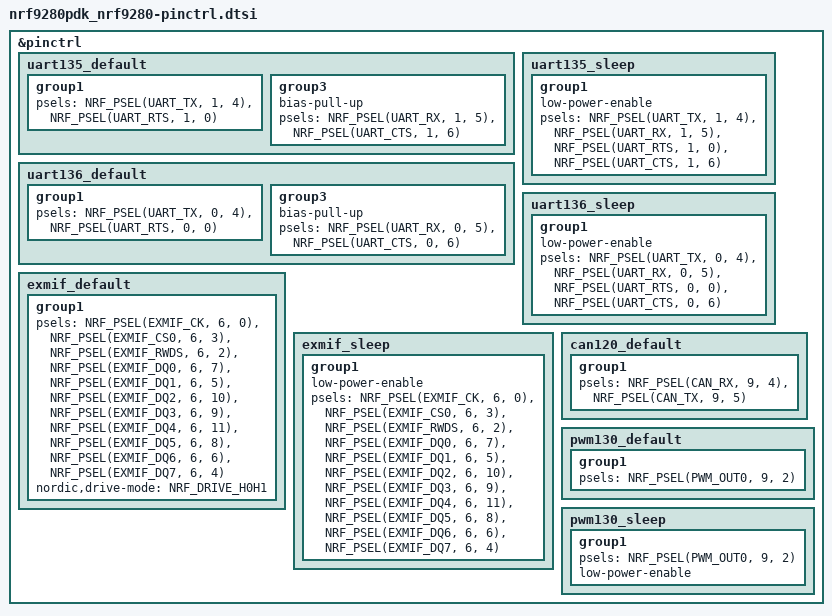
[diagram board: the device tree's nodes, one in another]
/*
 * Copyright (c) 2024 Nordic Semiconductor ASA
 *
 * SPDX-License-Identifier: Apache-2.0
 */

&pinctrl {
	/omit-if-no-ref/ uart135_default: uart135_default {
		group1 {
			psels = <NRF_PSEL(UART_TX, 1, 4)>,
				<NRF_PSEL(UART_RTS, 1, 0)>;
		};

		group3 {
			bias-pull-up;
			psels = <NRF_PSEL(UART_RX, 1, 5)>,
				<NRF_PSEL(UART_CTS, 1, 6)>;
		};
	};

	/omit-if-no-ref/ uart135_sleep: uart135_sleep {
		group1 {
			low-power-enable;
			psels = <NRF_PSEL(UART_TX, 1, 4)>,
				<NRF_PSEL(UART_RX, 1, 5)>,
				<NRF_PSEL(UART_RTS, 1, 0)>,
				<NRF_PSEL(UART_CTS, 1, 6)>;
		};
	};

	/omit-if-no-ref/ uart136_default: uart136_default {
		group1 {
			psels = <NRF_PSEL(UART_TX, 0, 4)>,
				<NRF_PSEL(UART_RTS, 0, 0)>;
		};

		group3 {
			bias-pull-up;
			psels = <NRF_PSEL(UART_RX, 0, 5)>,
				<NRF_PSEL(UART_CTS, 0, 6)>;
		};
	};

	/omit-if-no-ref/ uart136_sleep: uart136_sleep {
		group1 {
			low-power-enable;
			psels = <NRF_PSEL(UART_TX, 0, 4)>,
				<NRF_PSEL(UART_RX, 0, 5)>,
				<NRF_PSEL(UART_RTS, 0, 0)>,
				<NRF_PSEL(UART_CTS, 0, 6)>;
		};
	};

	/omit-if-no-ref/ exmif_default: exmif_default {
		group1 {
			psels = <NRF_PSEL(EXMIF_CK, 6, 0)>,
				<NRF_PSEL(EXMIF_CS0, 6, 3)>,
				<NRF_PSEL(EXMIF_RWDS, 6, 2)>,
				<NRF_PSEL(EXMIF_DQ0, 6, 7)>,
				<NRF_PSEL(EXMIF_DQ1, 6, 5)>,
				<NRF_PSEL(EXMIF_DQ2, 6, 10)>,
				<NRF_PSEL(EXMIF_DQ3, 6, 9)>,
				<NRF_PSEL(EXMIF_DQ4, 6, 11)>,
				<NRF_PSEL(EXMIF_DQ5, 6, 8)>,
				<NRF_PSEL(EXMIF_DQ6, 6, 6)>,
				<NRF_PSEL(EXMIF_DQ7, 6, 4)>;
			nordic,drive-mode = <NRF_DRIVE_H0H1>;
		};
	};

	/omit-if-no-ref/ exmif_sleep: exmif_sleep {
		group1 {
			low-power-enable;
			psels = <NRF_PSEL(EXMIF_CK, 6, 0)>,
				<NRF_PSEL(EXMIF_CS0, 6, 3)>,
				<NRF_PSEL(EXMIF_RWDS, 6, 2)>,
				<NRF_PSEL(EXMIF_DQ0, 6, 7)>,
				<NRF_PSEL(EXMIF_DQ1, 6, 5)>,
				<NRF_PSEL(EXMIF_DQ2, 6, 10)>,
				<NRF_PSEL(EXMIF_DQ3, 6, 9)>,
				<NRF_PSEL(EXMIF_DQ4, 6, 11)>,
				<NRF_PSEL(EXMIF_DQ5, 6, 8)>,
				<NRF_PSEL(EXMIF_DQ6, 6, 6)>,
				<NRF_PSEL(EXMIF_DQ7, 6, 4)>;
		};
	};

	/omit-if-no-ref/ can120_default: can120_default {
		group1 {
			psels = <NRF_PSEL(CAN_RX, 9, 4)>,
				<NRF_PSEL(CAN_TX, 9, 5)>;
		};
	};

	/omit-if-no-ref/ pwm130_default: pwm130_default {
		group1 {
			psels = <NRF_PSEL(PWM_OUT0, 9, 2)>;
		};
	};

	/omit-if-no-ref/ pwm130_sleep: pwm130_sleep {
		group1 {
			psels = <NRF_PSEL(PWM_OUT0, 9, 2)>;
			low-power-enable;
		};
	};
};
